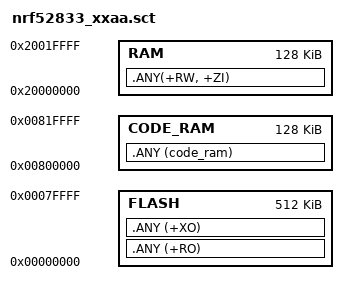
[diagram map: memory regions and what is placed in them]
LOAD 0x00000000 0x00080000
{
    FLASH 0x00000000 0x00080000
    {
    
        .ANY (+RO)
        .ANY (+XO)
    }

    RAM 0x20000000 0x00020000
    {
    .ANY(+RW, +ZI) ; RW data and ZI data
    }
    CODE_RAM 0x00800000 0x00020000
    {
    .ANY (code_ram) ; Code allocated to RAM blocks
    }
}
